# f29h85x_hsm_sm4_regs register map
Vendor: Texas Instruments
Peripheral module from a debugger description file (folder HSM).
Registers are 32-bit, read-write, no defined reset value unless marked. A register's access mark holds for its fields unless they carry their own. Offsets are as the file gives them; lines under a group give offsets from that group; [hi:lo] are bit positions; {n}, {i} and the like mark numbered series; 'fields as' and 'values as' point back to an identical list; <NAME> marks a mode.

## HSM_SM4 — HSM SM4 Registers
{0x0+4i} SM4_DATA_IN_{i} (i=0..3)
  [31:0] DATA_IN
{0x20+4i} SM4_KEY_IN_{i} (i=0..3)
  [31:0] KEY_IN
{0x40+4i} SM4_PARAM_IN_{i} (i=0..3)
  [31:0] PARAM_IN
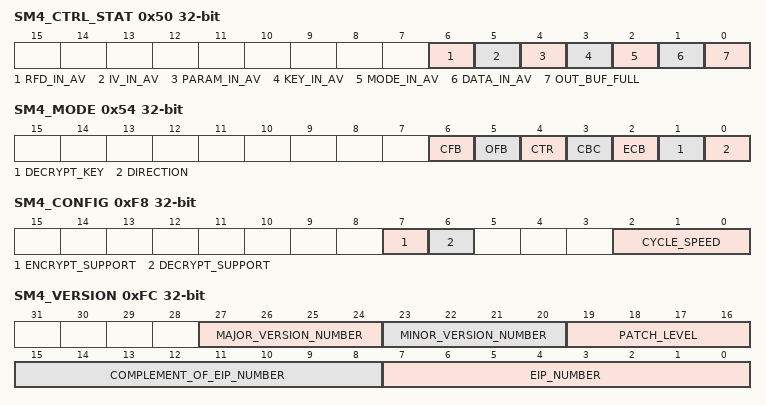
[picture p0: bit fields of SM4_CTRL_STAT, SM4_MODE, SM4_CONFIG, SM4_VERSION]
0x50 SM4_CTRL_STAT access per field
  [6] RFD_IN_AV ro, [5] IV_IN_AV rw, [4] PARAM_IN_AV rw, [3] KEY_IN_AV rw, [2] MODE_IN_AV rw, [1] DATA_IN_AV rw, [0] OUT_BUF_FULL rw
0x54 SM4_MODE access per field
  [6] CFB rw, [5] OFB rw, [4] CTR rw, [3] CBC rw, [2] ECB rw, [1] DECRYPT_KEY rw, [0] DIRECTION rw
{0x58+4i} SM4_DATA_OUT_{i} ro (i=0..3)
  [31:0] DATA_OUT
{0x68+4i} SM4_IV_IN_OUT_{i} (i=0..3)
  [31:0] IV
0xF8 SM4_CONFIG ro
  [7] ENCRYPT_SUPPORT, [6] DECRYPT_SUPPORT, [2:0] CYCLE_SPEED
0xFC SM4_VERSION ro
  [27:24] MAJOR_VERSION_NUMBER, [23:20] MINOR_VERSION_NUMBER, [19:16] PATCH_LEVEL, [15:8] COMPLEMENT_OF_EIP_NUMBER, [7:0] EIP_NUMBER
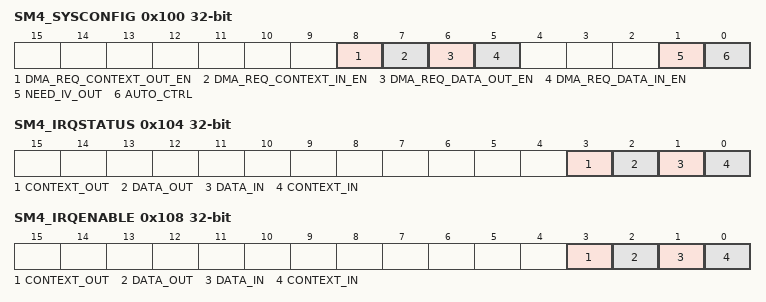
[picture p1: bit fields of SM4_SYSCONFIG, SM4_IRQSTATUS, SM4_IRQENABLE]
0x100 SM4_SYSCONFIG — SM4 sysconfig registers
  [8] DMA_REQ_CONTEXT_OUT_EN, [7] DMA_REQ_CONTEXT_IN_EN, [6] DMA_REQ_DATA_OUT_EN, [5] DMA_REQ_DATA_IN_EN, [1] NEED_IV_OUT, [0] AUTO_CTRL
0x104 SM4_IRQSTATUS — SM4 irqstatus registers
  [3] CONTEXT_OUT, [2] DATA_OUT, [1] DATA_IN, [0] CONTEXT_IN
0x108 SM4_IRQENABLE — SM4 irqenable registers
  [3] CONTEXT_OUT, [2] DATA_OUT, [1] DATA_IN, [0] CONTEXT_IN
0x10C SM4_LENGTH — SM4 length registers
